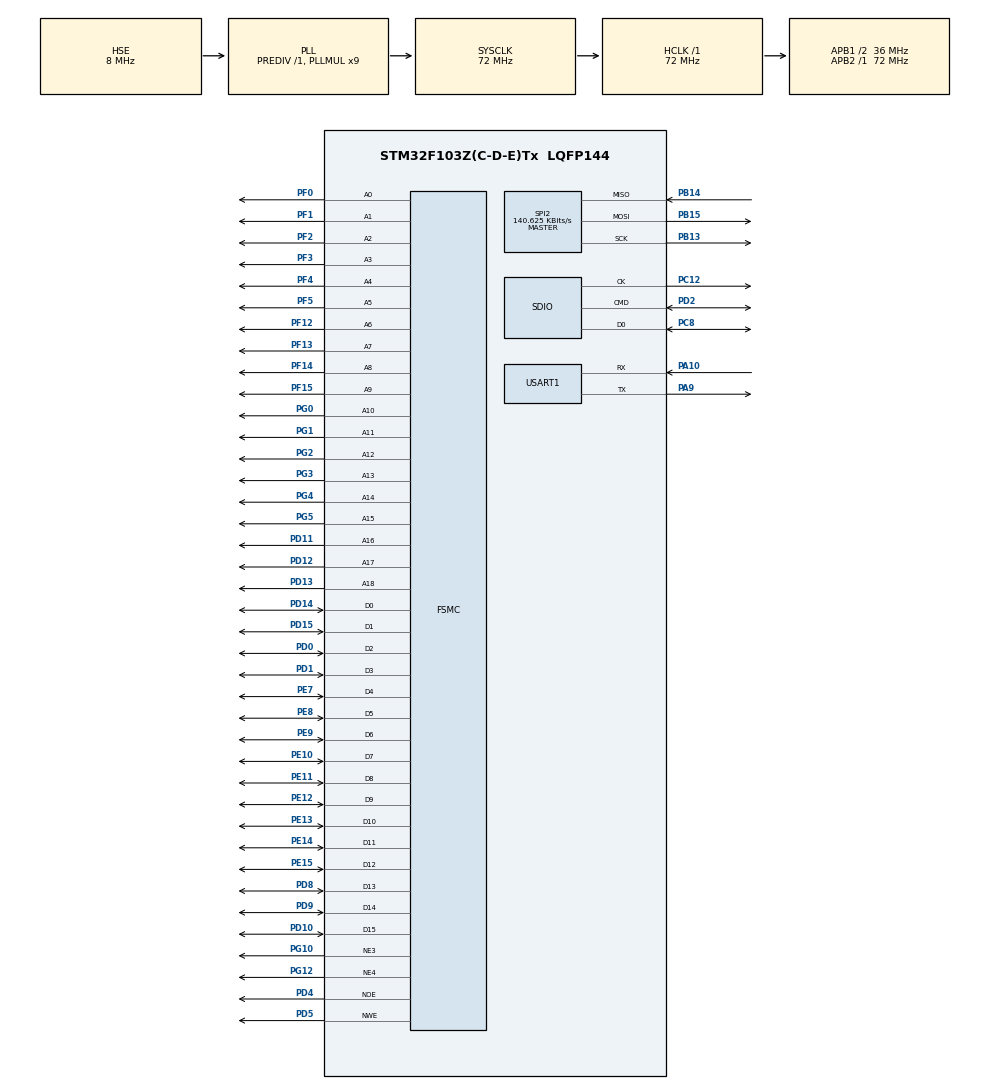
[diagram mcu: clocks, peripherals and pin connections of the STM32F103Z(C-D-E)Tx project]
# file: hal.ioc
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FREERTOS.Tasks01=defaultTask,24,128,StartDefaultTask,Default,NULL,Dynamic,NULL,NULL;LED_Task,24,256,StartTask02,Default,NULL,Dynamic,NULL,NULL
FREERTOS.configTOTAL_HEAP_SIZE=10240
FSMC.AddressSetupTime1=0
FSMC.AddressSetupTime4=0xf
FSMC.BusTurnAroundDuration1=0
FSMC.BusTurnAroundDuration4=0
FSMC.DataSetupTime1=8
FSMC.DataSetupTime4=60
FSMC.ExtendedAddressSetupTime4=9
FSMC.ExtendedBusTurnAroundDuration4=0
FSMC.ExtendedDataSetupTime4=8
FSMC.ExtendedMode4=FSMC_EXTENDED_MODE_ENABLE
FSMC.WriteOperation1=FSMC_WRITE_OPERATION_ENABLE
Mcu.Family=STM32F1
Mcu.Name=STM32F103Z(C-D-E)Tx
Mcu.Package=LQFP144
NVIC.PriorityGroup=NVIC_PRIORITYGROUP_4
NVIC.TIM4_IRQn=true\:5\:2\:false\:false\:true\:true\:true\:true\:true
NVIC.USART1_IRQn=true\:3\:2\:true\:false\:true\:true\:true\:true\:true
OSC_IN.Mode=HSE-External-Oscillator
OSC_IN.Signal=RCC_OSC_IN
OSC_OUT.Mode=HSE-External-Oscillator
OSC_OUT.Signal=RCC_OSC_OUT
PA10.Mode=Asynchronous
PA10.Signal=USART1_RX
PA13.Mode=JTAG_5_pins
PA13.Signal=SYS_JTMS-SWDIO
PA14.Mode=JTAG_5_pins
PA14.Signal=SYS_JTCK-SWCLK
PA15.Mode=JTAG_5_pins
PA15.Signal=SYS_JTDI
PA9.Mode=Asynchronous
PA9.Signal=USART1_TX
PB13.Mode=Full_Duplex_Master
PB13.Signal=SPI2_SCK
PB14.Mode=Full_Duplex_Master
PB14.Signal=SPI2_MISO
PB15.Mode=Full_Duplex_Master
PB15.Signal=SPI2_MOSI
PB3.Mode=JTAG_5_pins
PB3.Signal=SYS_JTDO-TRACESWO
PB4.Mode=JTAG_5_pins
PB4.Signal=SYS_NJTRST
PC12.Mode=SD_1_bit
PC12.Signal=SDIO_CK
PC14-OSC32_IN.Mode=LSE-External-Oscillator
PC14-OSC32_IN.Signal=RCC_OSC32_IN
PC15-OSC32_OUT.Mode=LSE-External-Oscillator
PC15-OSC32_OUT.Signal=RCC_OSC32_OUT
PC8.Mode=SD_1_bit
PC8.Signal=SDIO_D0
PD0.Signal=FSMC_D2_DA2
PD1.Signal=FSMC_D3_DA3
PD10.Signal=FSMC_D15_DA15
PD11.Signal=FSMC_A16_CLE
PD12.Signal=FSMC_A17_ALE
PD13.Signal=FSMC_A18
PD14.Signal=FSMC_D0_DA0
PD15.Signal=FSMC_D1_DA1
PD2.Mode=SD_1_bit
PD2.Signal=SDIO_CMD
PD4.Signal=FSMC_NOE
PD5.Signal=FSMC_NWE
PD8.Signal=FSMC_D13_DA13
PD9.Signal=FSMC_D14_DA14
PE10.Signal=FSMC_D7_DA7
PE11.Signal=FSMC_D8_DA8
PE12.Signal=FSMC_D9_DA9
PE13.Signal=FSMC_D10_DA10
PE14.Signal=FSMC_D11_DA11
PE15.Signal=FSMC_D12_DA12
PE7.Signal=FSMC_D4_DA4
PE8.Signal=FSMC_D5_DA5
PE9.Signal=FSMC_D6_DA6
PF0.Signal=FSMC_A0
PF1.Signal=FSMC_A1
PF12.Signal=FSMC_A6
PF13.Signal=FSMC_A7
PF14.Signal=FSMC_A8
PF15.Signal=FSMC_A9
PF2.Signal=FSMC_A2
PF3.Signal=FSMC_A3
PF4.Signal=FSMC_A4
PF5.Signal=FSMC_A5
PG0.Signal=FSMC_A10
PG1.Signal=FSMC_A11
PG10.Mode=NorPsramChipSelect3_1
PG10.Signal=FSMC_NE3
PG12.Mode=NorPsramChipSelect4_4
PG12.Signal=FSMC_NE4
PG2.Signal=FSMC_A12
PG3.Signal=FSMC_A13
PG4.Signal=FSMC_A14
PG5.Signal=FSMC_A15
ProjectManager.HeapSize=0x200
ProjectManager.StackSize=0x400
ProjectManager.TargetToolchain=STM32CubeIDE
RCC.AHBFreq_Value=72000000
RCC.APB1CLKDivider=RCC_HCLK_DIV2
RCC.APB1Freq_Value=36000000
RCC.APB1TimFreq_Value=72000000
RCC.APB2Freq_Value=72000000
RCC.APB2TimFreq_Value=72000000
RCC.HCLKFreq_Value=72000000
RCC.PLLMUL=RCC_PLL_MUL9
RCC.PLLSourceVirtual=RCC_PLLSOURCE_HSE
RCC.SYSCLKFreq_VALUE=72000000
RCC.SYSCLKSource=RCC_SYSCLKSOURCE_PLLCLK
RCC.USBFreq_Value=72000000
SDIO.ClockDiv=4
SH.FSMC_A0.0=FSMC_A0,19b-a1
SH.FSMC_A1.0=FSMC_A1,19b-a1
SH.FSMC_A10.0=FSMC_A10,A10_4
SH.FSMC_A10.1=FSMC_A10,19b-a1
SH.FSMC_A11.0=FSMC_A11,19b-a1
SH.FSMC_A12.0=FSMC_A12,19b-a1
SH.FSMC_A13.0=FSMC_A13,19b-a1
SH.FSMC_A14.0=FSMC_A14,19b-a1
SH.FSMC_A15.0=FSMC_A15,19b-a1
SH.FSMC_A16_CLE.0=FSMC_A16,19b-a1
SH.FSMC_A17_ALE.0=FSMC_A17,19b-a1
SH.FSMC_A18.0=FSMC_A18,19b-a1
SH.FSMC_A2.0=FSMC_A2,19b-a1
SH.FSMC_A3.0=FSMC_A3,19b-a1
SH.FSMC_A4.0=FSMC_A4,19b-a1
SH.FSMC_A5.0=FSMC_A5,19b-a1
SH.FSMC_A6.0=FSMC_A6,19b-a1
SH.FSMC_A7.0=FSMC_A7,19b-a1
SH.FSMC_A8.0=FSMC_A8,19b-a1
SH.FSMC_A9.0=FSMC_A9,19b-a1
SH.FSMC_D0_DA0.0=FSMC_D0,16b-d4
SH.FSMC_D0_DA0.1=FSMC_D0,16b-d1
SH.FSMC_D10_DA10.0=FSMC_D10,16b-d4
SH.FSMC_D10_DA10.1=FSMC_D10,16b-d1
SH.FSMC_D11_DA11.0=FSMC_D11,16b-d4
SH.FSMC_D11_DA11.1=FSMC_D11,16b-d1
SH.FSMC_D12_DA12.0=FSMC_D12,16b-d4
SH.FSMC_D12_DA12.1=FSMC_D12,16b-d1
SH.FSMC_D13_DA13.0=FSMC_D13,16b-d4
SH.FSMC_D13_DA13.1=FSMC_D13,16b-d1
SH.FSMC_D14_DA14.0=FSMC_D14,16b-d4
SH.FSMC_D14_DA14.1=FSMC_D14,16b-d1
SH.FSMC_D15_DA15.0=FSMC_D15,16b-d4
SH.FSMC_D15_DA15.1=FSMC_D15,16b-d1
SH.FSMC_D1_DA1.0=FSMC_D1,16b-d4
SH.FSMC_D1_DA1.1=FSMC_D1,16b-d1
SH.FSMC_D2_DA2.0=FSMC_D2,16b-d4
SH.FSMC_D2_DA2.1=FSMC_D2,16b-d1
SH.FSMC_D3_DA3.0=FSMC_D3,16b-d4
SH.FSMC_D3_DA3.1=FSMC_D3,16b-d1
SH.FSMC_D4_DA4.0=FSMC_D4,16b-d4
SH.FSMC_D4_DA4.1=FSMC_D4,16b-d1
SH.FSMC_D5_DA5.0=FSMC_D5,16b-d4
SH.FSMC_D5_DA5.1=FSMC_D5,16b-d1
SH.FSMC_D6_DA6.0=FSMC_D6,16b-d4
SH.FSMC_D6_DA6.1=FSMC_D6,16b-d1
SH.FSMC_D7_DA7.0=FSMC_D7,16b-d4
SH.FSMC_D7_DA7.1=FSMC_D7,16b-d1
SH.FSMC_D8_DA8.0=FSMC_D8,16b-d4
SH.FSMC_D8_DA8.1=FSMC_D8,16b-d1
SH.FSMC_D9_DA9.0=FSMC_D9,16b-d4
SH.FSMC_D9_DA9.1=FSMC_D9,16b-d1
SH.FSMC_NOE.0=FSMC_NOE,Lcd4
SH.FSMC_NOE.1=FSMC_NOE,Sram1
SH.FSMC_NWE.0=FSMC_NWE,Lcd4
SH.FSMC_NWE.1=FSMC_NWE,Sram1
SPI2.BaudRatePrescaler=SPI_BAUDRATEPRESCALER_256
SPI2.CLKPhase=SPI_PHASE_2EDGE
SPI2.CLKPolarity=SPI_POLARITY_HIGH
SPI2.CalculateBaudRate=140.625 KBits/s
SPI2.Direction=SPI_DIRECTION_2LINES
SPI2.Mode=SPI_MODE_MASTER
SPI2.VirtualType=VM_MASTER
TIM4.Period=999
TIM4.Prescaler=71
USART1.VirtualMode=VM_ASYNC
VP_FREERTOS_VS_CMSIS_V2.Mode=CMSIS_V2
VP_TIM4_VS_ClockSourceINT.Mode=Internal
board=custom

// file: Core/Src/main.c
/* USER CODE BEGIN Header */
/**
  ******************************************************************************
  * @file           : main.c
  * @brief          : Main program body
  ******************************************************************************
  * @attention
  *
  * Copyright (c) 2024 STMicroelectronics.
  * All rights reserved.
  *
  * This software is licensed under terms that can be found in the LICENSE file
  * in the root directory of this software component.
  * If no LICENSE file comes with this software, it is provided AS-IS.
  *
  ******************************************************************************
  */
/* USER CODE END Header */
#include "main.h"
#include "cmsis_os.h"
#include "sdio.h"
#include "spi.h"
#include "tim.h"
#include "usart.h"
#include "gpio.h"
#include "fsmc.h"

/* USER CODE BEGIN Includes */
#include "led.h"
/* USER CODE END Includes */

void SystemClock_Config(void);

void MX_FREERTOS_Init(void);

int main(void) {

    /* MCU Configuration--------------------------------------------------------*/

    /* Reset of all peripherals, Initializes the Flash interface and the Systick. */
    HAL_Init();

    /* Configure the system clock */
    SystemClock_Config();

    /* Initialize all configured peripherals */
    MX_GPIO_Init();
    MX_FSMC_Init();
    MX_USART1_UART_Init();
    MX_SPI2_Init();
    MX_SDIO_SD_Init();
    MX_TIM4_Init();
    /* USER CODE BEGIN 2 */
    LED_Init();
    /* USER CODE END 2 */

    /* Init scheduler */
    osKernelInitialize();

    /* Call init function for freertos objects (in cmsis_os2.c) */
    MX_FREERTOS_Init();

    /* Start scheduler */
    osKernelStart();

    /* We should never get here as control is now taken by the scheduler */

    /* Infinite loop */
    while (1) {

    }
}

void SystemClock_Config(void) {
    RCC_OscInitTypeDef RCC_OscInitStruct = {0};
    RCC_ClkInitTypeDef RCC_ClkInitStruct = {0};

    /** Initializes the RCC Oscillators according to the specified parameters
    * in the RCC_OscInitTypeDef structure.
    */
    RCC_OscInitStruct.OscillatorType = RCC_OSCILLATORTYPE_HSE;
    RCC_OscInitStruct.HSEState = RCC_HSE_ON;
    RCC_OscInitStruct.HSEPredivValue = RCC_HSE_PREDIV_DIV1;
    RCC_OscInitStruct.HSIState = RCC_HSI_ON;
    RCC_OscInitStruct.PLL.PLLState = RCC_PLL_ON;
    RCC_OscInitStruct.PLL.PLLSource = RCC_PLLSOURCE_HSE;
    RCC_OscInitStruct.PLL.PLLMUL = RCC_PLL_MUL9;
    if (HAL_RCC_OscConfig(&RCC_OscInitStruct) != HAL_OK) {
        Error_Handler();
    }

    /** Initializes the CPU, AHB and APB buses clocks
    */
    RCC_ClkInitStruct.ClockType = RCC_CLOCKTYPE_HCLK | RCC_CLOCKTYPE_SYSCLK
                                  | RCC_CLOCKTYPE_PCLK1 | RCC_CLOCKTYPE_PCLK2;
    RCC_ClkInitStruct.SYSCLKSource = RCC_SYSCLKSOURCE_PLLCLK;
    RCC_ClkInitStruct.AHBCLKDivider = RCC_SYSCLK_DIV1;
    RCC_ClkInitStruct.APB1CLKDivider = RCC_HCLK_DIV2;
    RCC_ClkInitStruct.APB2CLKDivider = RCC_HCLK_DIV1;

    if (HAL_RCC_ClockConfig(&RCC_ClkInitStruct, FLASH_LATENCY_2) != HAL_OK) {
        Error_Handler();
    }
}

void Error_Handler(void) {
    __disable_irq();
    while (1) {
    }
}

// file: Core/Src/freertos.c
/* USER CODE BEGIN Header */
/**
  ******************************************************************************
  * File Name          : freertos.c
  * Description        : Code for freertos applications
  ******************************************************************************
  * @attention
  *
  * Copyright (c) 2024 STMicroelectronics.
  * All rights reserved.
  *
  * This software is licensed under terms that can be found in the LICENSE file
  * in the root directory of this software component.
  * If no LICENSE file comes with this software, it is provided AS-IS.
  *
  ******************************************************************************
  */
/* USER CODE END Header */

#include "FreeRTOS.h"
#include "task.h"
#include "main.h"
#include "cmsis_os.h"

/* USER CODE BEGIN Includes */
#include "led.h"
/* USER CODE END Includes */

/* Definitions for defaultTask */
osThreadId_t defaultTaskHandle;
const osThreadAttr_t defaultTask_attributes = {
        .name = "defaultTask",
        .stack_size = 128 * 4,
        .priority = (osPriority_t) osPriorityNormal,
};
/* Definitions for LED_Task */
osThreadId_t LED_TaskHandle;
const osThreadAttr_t LED_Task_attributes = {
        .name = "LED_Task",
        .stack_size = 256 * 4,
        .priority = (osPriority_t) osPriorityNormal,
};

void StartDefaultTask(void *argument);

void StartTask02(void *argument);

void MX_FREERTOS_Init(void); /* (MISRA C 2004 rule 8.1) */

void MX_FREERTOS_Init(void) {

    /* Create the thread(s) */
    /* creation of defaultTask */
    defaultTaskHandle = osThreadNew(StartDefaultTask, NULL, &defaultTask_attributes);

    /* creation of LED_Task */
    LED_TaskHandle = osThreadNew(StartTask02, NULL, &LED_Task_attributes);

}

void StartDefaultTask(void *argument) {
    for (;;) {
        osDelay(1);
    }
}

void StartTask02(void *argument) {
    /* USER CODE BEGIN StartTask02 */
    /* Infinite loop */
    for (;;) {
        LED1 = !LED1;
        osDelay(500);
    }
    /* USER CODE END StartTask02 */
}
